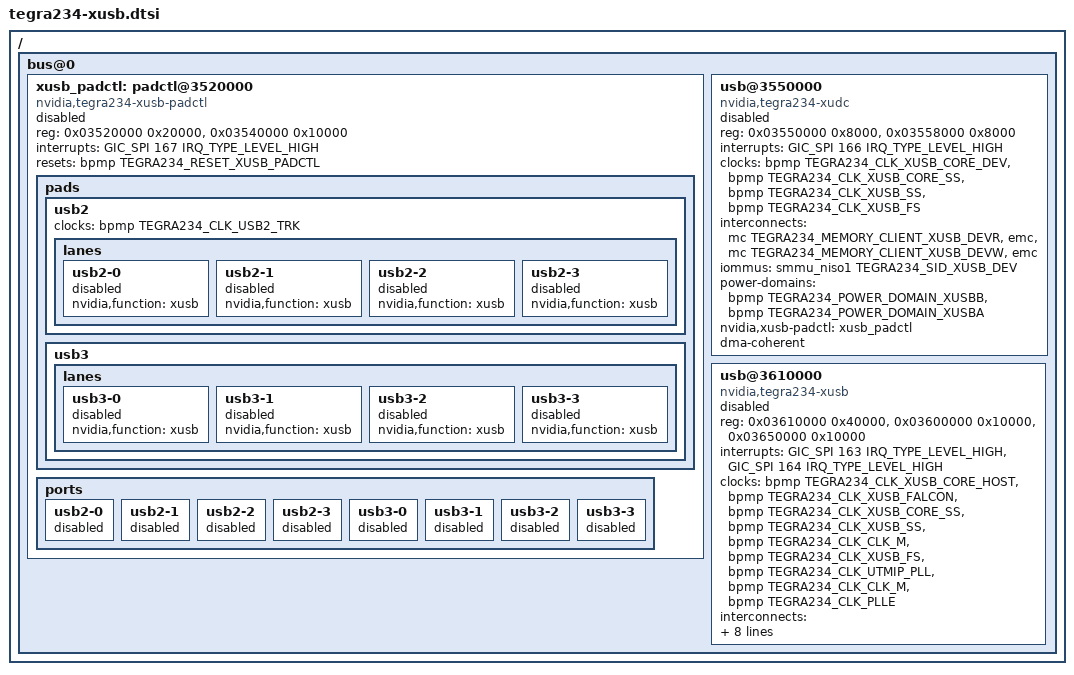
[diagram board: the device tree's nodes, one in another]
// SPDX-License-Identifier: GPL-2.0

#include <dt-bindings/clock/tegra234-clock.h>
#include <dt-bindings/interrupt-controller/arm-gic.h>
#include <dt-bindings/memory/tegra234-mc.h>
#include <dt-bindings/reset/tegra234-reset.h>

/ {
	bus@0 {
		xusb_padctl: padctl@3520000 {
			compatible = "nvidia,tegra234-xusb-padctl";
			reg = <0x03520000 0x20000>,
			      <0x03540000 0x10000>;
			reg-names = "padctl", "ao";
			interrupts = <GIC_SPI 167 IRQ_TYPE_LEVEL_HIGH>;

			resets = <&bpmp TEGRA234_RESET_XUSB_PADCTL>;
			reset-names = "padctl";

			status = "disabled";

			pads {
				usb2 {
					clocks = <&bpmp TEGRA234_CLK_USB2_TRK>;
					clock-names = "trk";

					lanes {
						usb2-0 {
							nvidia,function = "xusb";
							status = "disabled";
							#phy-cells = <0>;
						};

						usb2-1 {
							nvidia,function = "xusb";
							status = "disabled";
							#phy-cells = <0>;
						};

						usb2-2 {
							nvidia,function = "xusb";
							status = "disabled";
							#phy-cells = <0>;
						};

						usb2-3 {
							nvidia,function = "xusb";
							status = "disabled";
							#phy-cells = <0>;
						};
					};
				};

				usb3 {
					lanes {
						usb3-0 {
							nvidia,function = "xusb";
							status = "disabled";
							#phy-cells = <0>;
						};

						usb3-1 {
							nvidia,function = "xusb";
							status = "disabled";
							#phy-cells = <0>;
						};

						usb3-2 {
							nvidia,function = "xusb";
							status = "disabled";
							#phy-cells = <0>;
						};

						usb3-3 {
							nvidia,function = "xusb";
							status = "disabled";
							#phy-cells = <0>;
						};
					};
				};
			};

			ports {
				usb2-0 {
					status = "disabled";
				};

				usb2-1 {
					status = "disabled";
				};

				usb2-2 {
					status = "disabled";
				};

				usb2-3 {
					status = "disabled";
				};

				usb3-0 {
					status = "disabled";
				};

				usb3-1 {
					status = "disabled";
				};

				usb3-2 {
					status = "disabled";
				};

				usb3-3 {
					status = "disabled";
				};
			};
		};

		usb@3550000 {
			compatible = "nvidia,tegra234-xudc";
			reg = <0x03550000 0x8000>,
			      <0x03558000 0x8000>;
			reg-names = "base", "fpci";
			interrupts = <GIC_SPI 166 IRQ_TYPE_LEVEL_HIGH>;
			clocks = <&bpmp TEGRA234_CLK_XUSB_CORE_DEV>,
				 <&bpmp TEGRA234_CLK_XUSB_CORE_SS>,
				 <&bpmp TEGRA234_CLK_XUSB_SS>,
				 <&bpmp TEGRA234_CLK_XUSB_FS>;
			clock-names = "dev", "ss", "ss_src", "fs_src";
			interconnects = <&mc TEGRA234_MEMORY_CLIENT_XUSB_DEVR &emc>,
					<&mc TEGRA234_MEMORY_CLIENT_XUSB_DEVW &emc>;
			interconnect-names = "dma-mem", "write";
			iommus = <&smmu_niso1 TEGRA234_SID_XUSB_DEV>;
			power-domains = <&bpmp TEGRA234_POWER_DOMAIN_XUSBB>,
					<&bpmp TEGRA234_POWER_DOMAIN_XUSBA>;
			power-domain-names = "dev", "ss";
			nvidia,xusb-padctl = <&xusb_padctl>;
			dma-coherent;
			status = "disabled";
		};

		usb@3610000 {
			compatible = "nvidia,tegra234-xusb";
			reg = <0x03610000 0x40000>,
			      <0x03600000 0x10000>,
			      <0x03650000 0x10000>;
			reg-names = "hcd", "fpci", "bar2";

			interrupts = <GIC_SPI 163 IRQ_TYPE_LEVEL_HIGH>,
				     <GIC_SPI 164 IRQ_TYPE_LEVEL_HIGH>;

			clocks = <&bpmp TEGRA234_CLK_XUSB_CORE_HOST>,
				 <&bpmp TEGRA234_CLK_XUSB_FALCON>,
				 <&bpmp TEGRA234_CLK_XUSB_CORE_SS>,
				 <&bpmp TEGRA234_CLK_XUSB_SS>,
				 <&bpmp TEGRA234_CLK_CLK_M>,
				 <&bpmp TEGRA234_CLK_XUSB_FS>,
				 <&bpmp TEGRA234_CLK_UTMIP_PLL>,
				 <&bpmp TEGRA234_CLK_CLK_M>,
				 <&bpmp TEGRA234_CLK_PLLE>;
			clock-names = "xusb_host", "xusb_falcon_src",
				      "xusb_ss", "xusb_ss_src", "xusb_hs_src",
				      "xusb_fs_src", "pll_u_480m", "clk_m",
				      "pll_e";
			interconnects = <&mc TEGRA234_MEMORY_CLIENT_XUSB_HOSTR &emc>,
					<&mc TEGRA234_MEMORY_CLIENT_XUSB_HOSTW &emc>;
			interconnect-names = "dma-mem", "write";
			iommus = <&smmu_niso1 TEGRA234_SID_XUSB_HOST>;

			power-domains = <&bpmp TEGRA234_POWER_DOMAIN_XUSBC>,
					<&bpmp TEGRA234_POWER_DOMAIN_XUSBA>;
			power-domain-names = "xusb_host", "xusb_ss";

			nvidia,xusb-padctl = <&xusb_padctl>;
			dma-coherent;
			status = "disabled";
		};
	};
};
